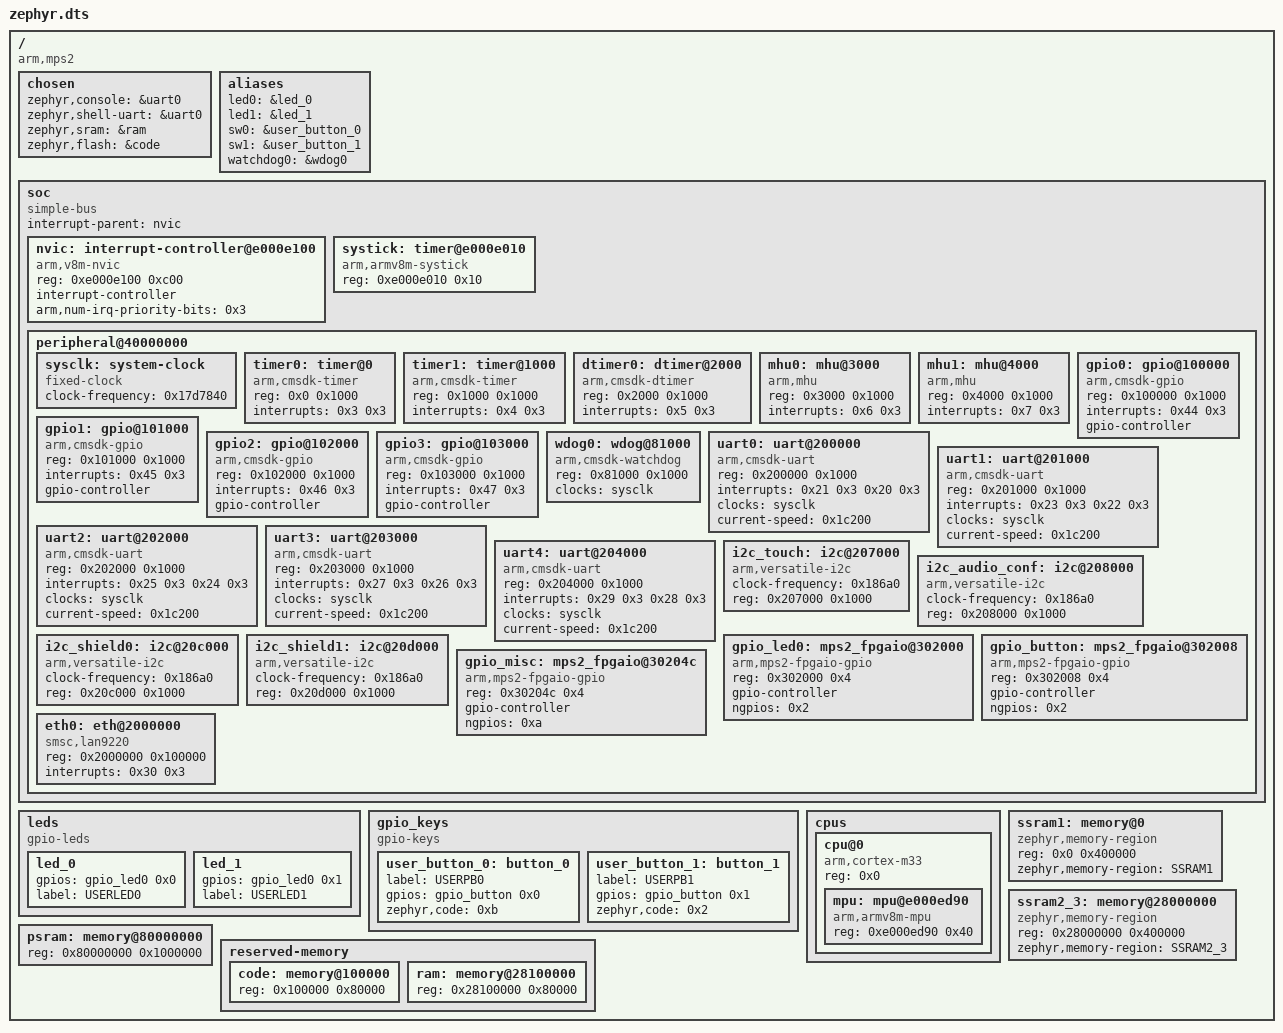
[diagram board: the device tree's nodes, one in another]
/dts-v1/;

/ {
	#address-cells = < 0x1 >;
	#size-cells = < 0x1 >;
	compatible = "arm,mps2";
	chosen {
		zephyr,console = &uart0;
		zephyr,shell-uart = &uart0;
		zephyr,sram = &ram;
		zephyr,flash = &code;
	};
	aliases {
		led0 = &led_0;
		led1 = &led_1;
		sw0 = &user_button_0;
		sw1 = &user_button_1;
		watchdog0 = &wdog0;
	};
	soc {
		#address-cells = < 0x1 >;
		#size-cells = < 0x1 >;
		compatible = "simple-bus";
		interrupt-parent = < &nvic >;
		ranges;
		nvic: interrupt-controller@e000e100 {
			#address-cells = < 0x1 >;
			compatible = "arm,v8m-nvic";
			reg = < 0xe000e100 0xc00 >;
			interrupt-controller;
			#interrupt-cells = < 0x2 >;
			arm,num-irq-priority-bits = < 0x3 >;
			phandle = < 0x1 >;
		};
		systick: timer@e000e010 {
			compatible = "arm,armv8m-systick";
			reg = < 0xe000e010 0x10 >;
		};
		peripheral@40000000 {
			#address-cells = < 0x1 >;
			#size-cells = < 0x1 >;
			ranges = < 0x0 0x40000000 0x10000000 >;
			sysclk: system-clock {
				compatible = "fixed-clock";
				clock-frequency = < 0x17d7840 >;
				#clock-cells = < 0x0 >;
				phandle = < 0x2 >;
			};
			timer0: timer@0 {
				compatible = "arm,cmsdk-timer";
				reg = < 0x0 0x1000 >;
				interrupts = < 0x3 0x3 >;
			};
			timer1: timer@1000 {
				compatible = "arm,cmsdk-timer";
				reg = < 0x1000 0x1000 >;
				interrupts = < 0x4 0x3 >;
			};
			dtimer0: dtimer@2000 {
				compatible = "arm,cmsdk-dtimer";
				reg = < 0x2000 0x1000 >;
				interrupts = < 0x5 0x3 >;
			};
			mhu0: mhu@3000 {
				compatible = "arm,mhu";
				reg = < 0x3000 0x1000 >;
				interrupts = < 0x6 0x3 >;
			};
			mhu1: mhu@4000 {
				compatible = "arm,mhu";
				reg = < 0x4000 0x1000 >;
				interrupts = < 0x7 0x3 >;
			};
			gpio0: gpio@100000 {
				compatible = "arm,cmsdk-gpio";
				reg = < 0x100000 0x1000 >;
				interrupts = < 0x44 0x3 >;
				gpio-controller;
				#gpio-cells = < 0x2 >;
			};
			gpio1: gpio@101000 {
				compatible = "arm,cmsdk-gpio";
				reg = < 0x101000 0x1000 >;
				interrupts = < 0x45 0x3 >;
				gpio-controller;
				#gpio-cells = < 0x2 >;
			};
			gpio2: gpio@102000 {
				compatible = "arm,cmsdk-gpio";
				reg = < 0x102000 0x1000 >;
				interrupts = < 0x46 0x3 >;
				gpio-controller;
				#gpio-cells = < 0x2 >;
			};
			gpio3: gpio@103000 {
				compatible = "arm,cmsdk-gpio";
				reg = < 0x103000 0x1000 >;
				interrupts = < 0x47 0x3 >;
				gpio-controller;
				#gpio-cells = < 0x2 >;
			};
			wdog0: wdog@81000 {
				compatible = "arm,cmsdk-watchdog";
				reg = < 0x81000 0x1000 >;
				clocks = < &sysclk >;
			};
			uart0: uart@200000 {
				compatible = "arm,cmsdk-uart";
				reg = < 0x200000 0x1000 >;
				interrupts = < 0x21 0x3 0x20 0x3 >;
				interrupt-names = "tx", "rx";
				clocks = < &sysclk >;
				current-speed = < 0x1c200 >;
			};
			uart1: uart@201000 {
				compatible = "arm,cmsdk-uart";
				reg = < 0x201000 0x1000 >;
				interrupts = < 0x23 0x3 0x22 0x3 >;
				interrupt-names = "tx", "rx";
				clocks = < &sysclk >;
				current-speed = < 0x1c200 >;
			};
			uart2: uart@202000 {
				compatible = "arm,cmsdk-uart";
				reg = < 0x202000 0x1000 >;
				interrupts = < 0x25 0x3 0x24 0x3 >;
				interrupt-names = "tx", "rx";
				clocks = < &sysclk >;
				current-speed = < 0x1c200 >;
			};
			uart3: uart@203000 {
				compatible = "arm,cmsdk-uart";
				reg = < 0x203000 0x1000 >;
				interrupts = < 0x27 0x3 0x26 0x3 >;
				interrupt-names = "tx", "rx";
				clocks = < &sysclk >;
				current-speed = < 0x1c200 >;
			};
			uart4: uart@204000 {
				compatible = "arm,cmsdk-uart";
				reg = < 0x204000 0x1000 >;
				interrupts = < 0x29 0x3 0x28 0x3 >;
				interrupt-names = "tx", "rx";
				clocks = < &sysclk >;
				current-speed = < 0x1c200 >;
			};
			i2c_touch: i2c@207000 {
				compatible = "arm,versatile-i2c";
				clock-frequency = < 0x186a0 >;
				#address-cells = < 0x1 >;
				#size-cells = < 0x0 >;
				reg = < 0x207000 0x1000 >;
			};
			i2c_audio_conf: i2c@208000 {
				compatible = "arm,versatile-i2c";
				clock-frequency = < 0x186a0 >;
				#address-cells = < 0x1 >;
				#size-cells = < 0x0 >;
				reg = < 0x208000 0x1000 >;
			};
			i2c_shield0: i2c@20c000 {
				compatible = "arm,versatile-i2c";
				clock-frequency = < 0x186a0 >;
				#address-cells = < 0x1 >;
				#size-cells = < 0x0 >;
				reg = < 0x20c000 0x1000 >;
			};
			i2c_shield1: i2c@20d000 {
				compatible = "arm,versatile-i2c";
				clock-frequency = < 0x186a0 >;
				#address-cells = < 0x1 >;
				#size-cells = < 0x0 >;
				reg = < 0x20d000 0x1000 >;
			};
			gpio_led0: mps2_fpgaio@302000 {
				compatible = "arm,mps2-fpgaio-gpio";
				reg = < 0x302000 0x4 >;
				gpio-controller;
				#gpio-cells = < 0x1 >;
				ngpios = < 0x2 >;
				phandle = < 0x3 >;
			};
			gpio_button: mps2_fpgaio@302008 {
				compatible = "arm,mps2-fpgaio-gpio";
				reg = < 0x302008 0x4 >;
				gpio-controller;
				#gpio-cells = < 0x1 >;
				ngpios = < 0x2 >;
				phandle = < 0x4 >;
			};
			gpio_misc: mps2_fpgaio@30204c {
				compatible = "arm,mps2-fpgaio-gpio";
				reg = < 0x30204c 0x4 >;
				gpio-controller;
				#gpio-cells = < 0x1 >;
				ngpios = < 0xa >;
			};
			eth0: eth@2000000 {
				compatible = "smsc,lan9220";
				reg = < 0x2000000 0x100000 >;
				interrupts = < 0x30 0x3 >;
			};
		};
	};
	leds {
		compatible = "gpio-leds";
		led_0: led_0 {
			gpios = < &gpio_led0 0x0 >;
			label = "USERLED0";
		};
		led_1: led_1 {
			gpios = < &gpio_led0 0x1 >;
			label = "USERLED1";
		};
	};
	gpio_keys {
		compatible = "gpio-keys";
		user_button_0: button_0 {
			label = "USERPB0";
			gpios = < &gpio_button 0x0 >;
			zephyr,code = < 0xb >;
		};
		user_button_1: button_1 {
			label = "USERPB1";
			gpios = < &gpio_button 0x1 >;
			zephyr,code = < 0x2 >;
		};
	};
	cpus {
		#address-cells = < 0x1 >;
		#size-cells = < 0x0 >;
		cpu@0 {
			device_type = "cpu";
			compatible = "arm,cortex-m33";
			reg = < 0x0 >;
			#address-cells = < 0x1 >;
			#size-cells = < 0x1 >;
			mpu: mpu@e000ed90 {
				compatible = "arm,armv8m-mpu";
				reg = < 0xe000ed90 0x40 >;
			};
		};
	};
	ssram1: memory@0 {
		compatible = "zephyr,memory-region", "mmio-sram";
		reg = < 0x0 0x400000 >;
		zephyr,memory-region = "SSRAM1";
	};
	ssram2_3: memory@28000000 {
		compatible = "zephyr,memory-region", "mmio-sram";
		reg = < 0x28000000 0x400000 >;
		zephyr,memory-region = "SSRAM2_3";
	};
	psram: memory@80000000 {
		device_type = "memory";
		reg = < 0x80000000 0x1000000 >;
	};
	reserved-memory {
		#address-cells = < 0x1 >;
		#size-cells = < 0x1 >;
		ranges;
		code: memory@100000 {
			reg = < 0x100000 0x80000 >;
		};
		ram: memory@28100000 {
			reg = < 0x28100000 0x80000 >;
		};
	};
};
